# K1921VK035 register map
Vendor: NIIET; Series: K1921VKx; File version: 2.10
CPU: CM4 r0p1, little endian, MPU, FPU, 3 interrupt priority bits
Registers are 32-bit, read-write, reset 0x0 unless marked. A register's access mark holds for its fields unless they carry their own. Offsets are from the block's base; [hi:lo] are bit positions; {n}, {i} and the like mark numbered series; 'fields as' and 'values as' point back to an identical list.

## PMU — Power management unit registers
Base 0x40042000
0x00 CFG — PMU Configuration Register
  [0] EN — Enable PMU
0x04 PUDEL — PMU Powerup Delay Value
  [15:0] VAL — Delay value for powerup peripheral blocks (in OSICLK ticks)
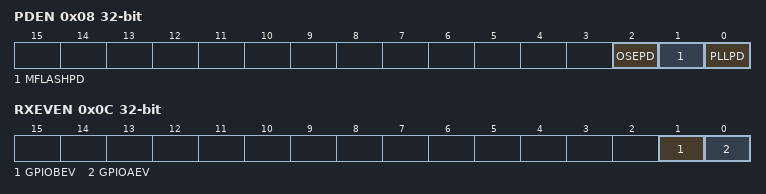
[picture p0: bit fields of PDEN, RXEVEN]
0x08 PDEN — PMU Enable Powerdown for peripheral
  [2] OSEPD — Enable powerdown for external oscillator
  [1] MFLASHPD — Enable powerdown for MFLASH
  [0] PLLPD — Enable powerdown for PLL
0x0C RXEVEN — PMU RX Event generation enable register
  [1] GPIOBEV — Enable RX event from GPIOB pins
  [0] GPIOAEV — Enable RX event from GPIOA pins

## WDT — Watchdog control registers
Base 0x40043000
0x00 LOAD — Watchdog Load Register
  [31:0] VAL
0x04 VALUE ro — Watchdog Value Register
  [31:0] VAL
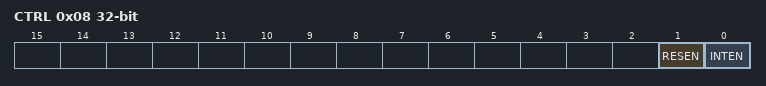
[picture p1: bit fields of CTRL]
0x08 CTRL — Watchdog Control Register
  [1] RESEN — Enable watchdog reset output
  [0] INTEN — Enable the interrupt event
0x0C INTCLR wo — Watchdog Clear Interrupt Register
  [31:0] WDTCLR
0x10 RIS ro — Watchdog Raw Interrupt Status Register
  [0] RAWWDTINT — Raw interrupt status from the counter
0x14 MIS ro — Watchdog Interrupt Status Register
  [0] WDTINT — Enabled interrupt status from the counter
0xC00 LOCK wo — Watchdog Lock Register
  [0] REGWRDIS — Disable write to all registers Watchdog

## TMR0 — TMR controller registers
Base 0x40048000
Same registers: TMR1 0x40049000, TMR2 0x4004A000, TMR3 0x4004B000
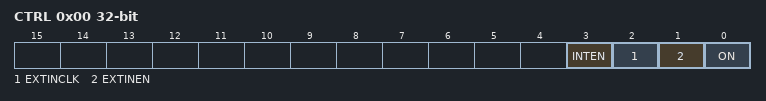
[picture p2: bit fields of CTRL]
0x00 CTRL — Control Timer register
  [3] INTEN — Enable Timer interrupt
  [2] EXTINCLK — Enable external input as CLK
  [1] EXTINEN — Enable external input as ENABLE
  [0] ON — Enable Timer
0x04 VALUE — Current value timer register
  [31:0] VAL
0x08 LOAD — Reload value timer register
  [31:0] VAL
0x0C INTSTATUS — Interrupt status register
  [0] INT — Timer interrupt flag
0x10 DMAREQ — DMA request register
  [0] EN
0x14 ADCSOC — ADC start of conversion register
  [0] EN

## UART0 — UART control registers
Base 0x40045000
Same registers: UART1 0x40046000
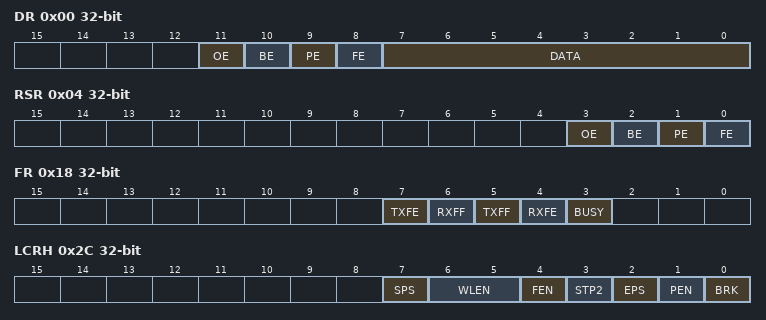
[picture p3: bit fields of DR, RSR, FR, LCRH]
0x00 DR — Data Register
  [11] OE ro — Overrun error
  [10] BE ro — Break error
  [9] PE ro — Parity error
  [8] FE ro — Framing error
  [7:0] DATA
0x04 RSR — Receive Status Register/Error Clear Register
  [3] OE — Overrun error
  [2] BE — Break error
  [1] PE — Parity error
  [0] FE — Framing error
0x18 FR ro — Flag Register
  [7] TXFE — Transmit FIFO empty
  [6] RXFF — Receive FIFO full
  [5] TXFF — Transmit FIFO full
  [4] RXFE — Receive FIFO empty
  [3] BUSY — UART busy
0x24 IBRD — Integer Baud Rate Register
  [15:0] DIVINT
0x28 FBRD — Fractional Baud Rate Register
  [5:0] DIVFRAC
0x2C LCRH — Line Control Register
  [7] SPS — Stick parity select
  [6:5] WLEN
    {v}={v+5} bit in informational word (v=0..3)
  [4] FEN — Enable FIFOs
  [3] STP2 — Two stop bits select
  [2] EPS — Even parity select
  [1] PEN — Parity enable
  [0] BRK — Send break
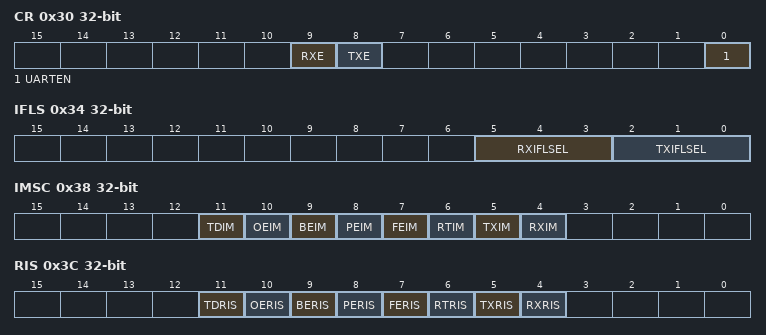
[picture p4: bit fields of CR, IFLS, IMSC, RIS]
0x30 CR — Control Register
  [9] RXE — Receive enable
  [8] TXE — Transmit enable
  [0] UARTEN — UART enable
0x34 IFLS — Interrupt FIFO Level Select Register
  [5:3] RXIFLSEL
    0=Lvl18 (interrupt on 1/8); 1=Lvl14 (interrupt on 1/4); 2=Lvl12 (interrupt on 1/2); 3=Lvl34 (interrupt on 3/4); 4=Lvl78 (interrupt on 7/8)
  [2:0] TXIFLSEL
    values as RXIFLSEL
0x38 IMSC — Interrupt Mask Set/Clear Register
  [11] TDIM — Transmit done interrupt mask
  [10] OEIM — Overrun error interrupt mask
  [9] BEIM — Break error interrupt mask
  [8] PEIM — Parity error interrupt mask
  [7] FEIM — Framing error interrupt mask
  [6] RTIM — Receive timeout interrupt mask
  [5] TXIM — Transmit interrupt mask
  [4] RXIM — Receive interrupt mask
0x3C RIS — Raw Interrupt Status Register
  [11] TDRIS — Transmit done raw interrupt status
  [10] OERIS ro — Overrun error interrupt status
  [9] BERIS ro — Break error interrupt status
  [8] PERIS ro — Parity error interrupt status
  [7] FERIS ro — Framing error interrupt status
  [6] RTRIS ro — Receive timeout interrupt status
  [5] TXRIS ro — Transmit interrupt status
  [4] RXRIS ro — Receive interrupt status
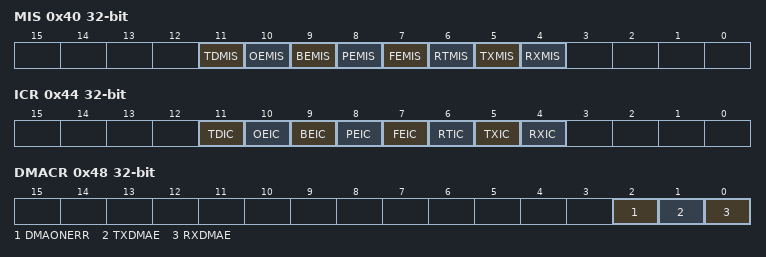
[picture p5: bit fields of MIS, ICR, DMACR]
0x40 MIS — Masked Interrupt Status Register
  [11] TDMIS — Transmit done masked interrupt status
  [10] OEMIS ro — Overrun error masked interrupt status
  [9] BEMIS ro — Break error masked interrupt status
  [8] PEMIS ro — Parity error masked interrupt status
  [7] FEMIS ro — Framing error masked interrupt status
  [6] RTMIS ro — Receive timeout masked interrupt status
  [5] TXMIS ro — Transmit masked interrupt status
  [4] RXMIS ro — Receive masked interrupt status
0x44 ICR — Interrupt Clear Register
  [11] TDIC — Transmit done interrupt clear
  [10] OEIC wo — Overrun error interrupt clear
  [9] BEIC wo — Break error interrupt clear
  [8] PEIC wo — Parity error interrupt clear
  [7] FEIC wo — Framing error interrupt clear
  [6] RTIC wo — Receive timeout interrupt clear
  [5] TXIC wo — Transmit interrupt clear
  [4] RXIC wo — Receive interrupt clear
0x48 DMACR — DMA Control Register
  [2] DMAONERR — DMA on error
  [1] TXDMAE — Transmit DMA enable
  [0] RXDMAE — Receive DMA enable
